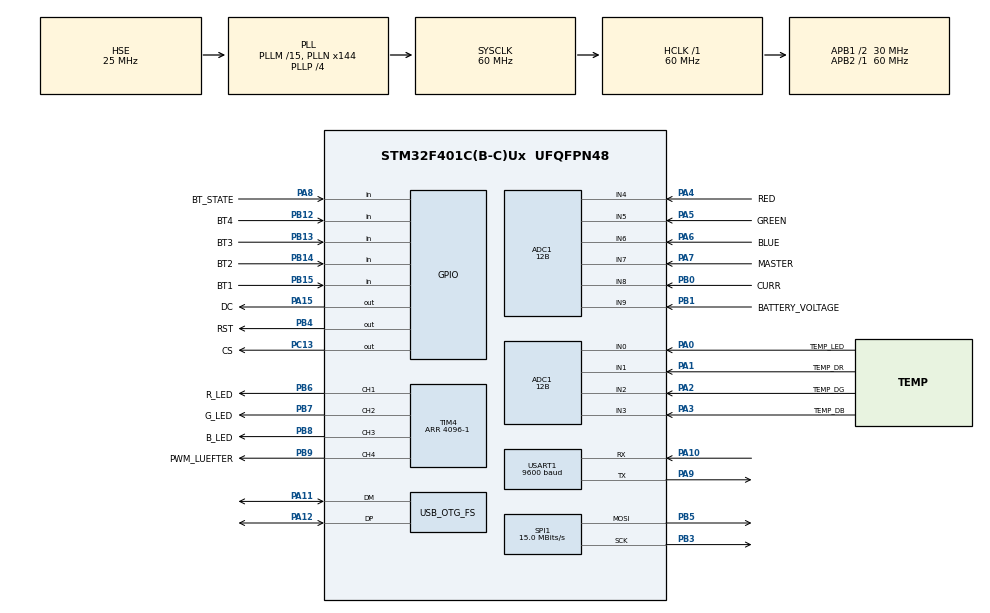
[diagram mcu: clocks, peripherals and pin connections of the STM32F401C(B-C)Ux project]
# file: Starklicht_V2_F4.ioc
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ADC1.Channel-0\#ChannelRegularConversion=ADC_CHANNEL_0
ADC1.Channel-1\#ChannelRegularConversion=ADC_CHANNEL_1
ADC1.Channel-2\#ChannelRegularConversion=ADC_CHANNEL_2
ADC1.Channel-3\#ChannelRegularConversion=ADC_CHANNEL_3
ADC1.Channel-4\#ChannelRegularConversion=ADC_CHANNEL_4
ADC1.Channel-5\#ChannelRegularConversion=ADC_CHANNEL_5
ADC1.Channel-6\#ChannelRegularConversion=ADC_CHANNEL_6
ADC1.Channel-7\#ChannelRegularConversion=ADC_CHANNEL_7
ADC1.Channel-8\#ChannelRegularConversion=ADC_CHANNEL_8
ADC1.Channel-9\#ChannelRegularConversion=ADC_CHANNEL_9
ADC1.ClockPrescaler=ADC_CLOCK_SYNC_PCLK_DIV8
ADC1.ContinuousConvMode=ENABLE
ADC1.DMAContinuousRequests=ENABLE
ADC1.EOCSelection=ADC_EOC_SINGLE_CONV
ADC1.ExternalTrigConv=ADC_SOFTWARE_START
ADC1.InjNumberOfConversion=0
ADC1.NbrOfConversion=10
ADC1.NbrOfConversionFlag=1
ADC1.Rank-0\#ChannelRegularConversion=1
ADC1.Rank-1\#ChannelRegularConversion=2
ADC1.Rank-2\#ChannelRegularConversion=3
ADC1.Rank-3\#ChannelRegularConversion=4
ADC1.Rank-4\#ChannelRegularConversion=5
ADC1.Rank-5\#ChannelRegularConversion=6
ADC1.Rank-6\#ChannelRegularConversion=7
ADC1.Rank-7\#ChannelRegularConversion=8
ADC1.Rank-8\#ChannelRegularConversion=9
ADC1.Rank-9\#ChannelRegularConversion=10
ADC1.Resolution=ADC_RESOLUTION_12B
ADC1.SamplingTime-0\#ChannelRegularConversion=ADC_SAMPLETIME_28CYCLES
ADC1.SamplingTime-1\#ChannelRegularConversion=ADC_SAMPLETIME_28CYCLES
ADC1.SamplingTime-2\#ChannelRegularConversion=ADC_SAMPLETIME_28CYCLES
ADC1.SamplingTime-3\#ChannelRegularConversion=ADC_SAMPLETIME_28CYCLES
ADC1.SamplingTime-4\#ChannelRegularConversion=ADC_SAMPLETIME_28CYCLES
ADC1.SamplingTime-5\#ChannelRegularConversion=ADC_SAMPLETIME_28CYCLES
ADC1.SamplingTime-6\#ChannelRegularConversion=ADC_SAMPLETIME_28CYCLES
ADC1.SamplingTime-7\#ChannelRegularConversion=ADC_SAMPLETIME_28CYCLES
ADC1.SamplingTime-8\#ChannelRegularConversion=ADC_SAMPLETIME_28CYCLES
ADC1.SamplingTime-9\#ChannelRegularConversion=ADC_SAMPLETIME_28CYCLES
ADC1.master=1
Dma.ADC1.0.Direction=DMA_PERIPH_TO_MEMORY
Dma.ADC1.0.FIFOMode=DMA_FIFOMODE_DISABLE
Dma.ADC1.0.Instance=DMA2_Stream4
Dma.ADC1.0.MemDataAlignment=DMA_MDATAALIGN_HALFWORD
Dma.ADC1.0.MemInc=DMA_MINC_ENABLE
Dma.ADC1.0.Mode=DMA_CIRCULAR
Dma.ADC1.0.PeriphDataAlignment=DMA_PDATAALIGN_HALFWORD
Dma.ADC1.0.PeriphInc=DMA_PINC_DISABLE
Dma.ADC1.0.Priority=DMA_PRIORITY_LOW
Dma.Request0=ADC1
Mcu.Family=STM32F4
Mcu.Name=STM32F401C(B-C)Ux
Mcu.Package=UFQFPN48
NVIC.DMA2_Stream4_IRQn=true\:0\:0\:false\:false\:true\:false\:true\:true
NVIC.OTG_FS_IRQn=true\:0\:0\:false\:false\:true\:false\:true\:true
NVIC.PriorityGroup=NVIC_PRIORITYGROUP_4
NVIC.USART1_IRQn=true\:0\:0\:false\:false\:true\:true\:true\:true
PA0-WKUP.GPIO_Label=TEMP_LED
PA0-WKUP.Signal=SharedAnalog_PA0
PA1.GPIO_Label=TEMP_DR
PA1.Signal=SharedAnalog_PA1
PA10.Mode=Asynchronous
PA10.Signal=USART1_RX
PA11.Mode=Device_Only
PA11.Signal=USB_OTG_FS_DM
PA12.Mode=Device_Only
PA12.Signal=USB_OTG_FS_DP
PA13.Mode=Serial_Wire
PA13.Signal=SYS_JTMS-SWDIO
PA14.Mode=Serial_Wire
PA14.Signal=SYS_JTCK-SWCLK
PA15.GPIO_Label=DC
PA15.Signal=GPIO_Output
PA2.GPIO_Label=TEMP_DG
PA2.Signal=SharedAnalog_PA2
PA3.GPIO_Label=TEMP_DB
PA3.Signal=SharedAnalog_PA3
PA4.GPIO_Label=RED
PA4.Signal=SharedAnalog_PA4
PA5.GPIO_Label=GREEN
PA5.Signal=SharedAnalog_PA5
PA6.GPIO_Label=BLUE
PA6.Signal=SharedAnalog_PA6
PA7.GPIO_Label=MASTER
PA7.Signal=SharedAnalog_PA7
PA8.GPIO_Label=BT_STATE
PA8.Signal=GPIO_Input
PA9.Mode=Asynchronous
PA9.Signal=USART1_TX
PB0.GPIO_Label=CURR
PB0.Signal=SharedAnalog_PB0
PB1.GPIO_Label=BATTERY_VOLTAGE
PB1.Signal=SharedAnalog_PB1
PB12.GPIO_Label=BT4
PB12.Signal=GPIO_Input
PB13.GPIO_Label=BT3
PB13.Signal=GPIO_Input
PB14.GPIO_Label=BT2
PB14.Signal=GPIO_Input
PB15.GPIO_Label=BT1
PB15.Signal=GPIO_Input
PB3.Mode=TX_Only_Simplex_Unidirect_Master
PB3.Signal=SPI1_SCK
PB4.GPIO_Label=RST
PB4.Signal=GPIO_Output
PB5.Mode=TX_Only_Simplex_Unidirect_Master
PB5.Signal=SPI1_MOSI
PB6.GPIO_Label=R_LED
PB6.Signal=S_TIM4_CH1
PB7.GPIO_Label=G_LED
PB7.Signal=S_TIM4_CH2
PB8.GPIO_Label=B_LED
PB8.Signal=S_TIM4_CH3
PB9.GPIO_Label=PWM_LUEFTER
PB9.Signal=S_TIM4_CH4
PC13-ANTI_TAMP.GPIO_Label=CS
PC13-ANTI_TAMP.Signal=GPIO_Output
PH0\ -\ OSC_IN.Mode=HSE-External-Oscillator
PH0\ -\ OSC_IN.Signal=RCC_OSC_IN
PH1\ -\ OSC_OUT.Mode=HSE-External-Oscillator
PH1\ -\ OSC_OUT.Signal=RCC_OSC_OUT
ProjectManager.HeapSize=0x200
ProjectManager.StackSize=0x400
ProjectManager.TargetToolchain=STM32CubeIDE
RCC.48MHZClocksFreq_Value=48000000
RCC.AHBFreq_Value=60000000
RCC.APB1CLKDivider=RCC_HCLK_DIV2
RCC.APB1Freq_Value=30000000
RCC.APB1TimFreq_Value=60000000
RCC.APB2Freq_Value=60000000
RCC.APB2TimFreq_Value=60000000
RCC.CortexFreq_Value=60000000
RCC.HCLKFreq_Value=60000000
RCC.HSE_VALUE=25000000
RCC.HSI_VALUE=16000000
RCC.LSE_VALUE=32768
RCC.PLLM=15
RCC.PLLN=144
RCC.PLLP=RCC_PLLP_DIV4
RCC.PLLQ=5
RCC.PLLSourceVirtual=RCC_PLLSOURCE_HSE
RCC.SYSCLKFreq_VALUE=60000000
RCC.SYSCLKSource=RCC_SYSCLKSOURCE_PLLCLK
RCC.VCOOutputFreq_Value=240000000
SH.S_TIM4_CH1.0=TIM4_CH1,PWM Generation1 CH1
SH.S_TIM4_CH2.0=TIM4_CH2,PWM Generation2 CH2
SH.S_TIM4_CH3.0=TIM4_CH3,PWM Generation3 CH3
SH.S_TIM4_CH4.0=TIM4_CH4,PWM Generation4 CH4
SH.SharedAnalog_PA0.0=GPIO_Analog
SH.SharedAnalog_PA0.1=ADC1_IN0,IN0
SH.SharedAnalog_PA1.0=GPIO_Analog
SH.SharedAnalog_PA1.1=ADC1_IN1,IN1
SH.SharedAnalog_PA2.0=GPIO_Analog
SH.SharedAnalog_PA2.1=ADC1_IN2,IN2
SH.SharedAnalog_PA3.0=GPIO_Analog
SH.SharedAnalog_PA3.1=ADC1_IN3,IN3
SH.SharedAnalog_PA4.0=GPIO_Analog
SH.SharedAnalog_PA4.1=ADC1_IN4,IN4
SH.SharedAnalog_PA5.0=GPIO_Analog
SH.SharedAnalog_PA5.1=ADC1_IN5,IN5
SH.SharedAnalog_PA6.0=GPIO_Analog
SH.SharedAnalog_PA6.1=ADC1_IN6,IN6
SH.SharedAnalog_PA7.0=GPIO_Analog
SH.SharedAnalog_PA7.1=ADC1_IN7,IN7
SH.SharedAnalog_PB0.0=GPIO_Analog
SH.SharedAnalog_PB0.1=ADC1_IN8,IN8
SH.SharedAnalog_PB1.0=GPIO_Analog
SH.SharedAnalog_PB1.1=ADC1_IN9,IN9
SPI1.BaudRatePrescaler=SPI_BAUDRATEPRESCALER_4
SPI1.CalculateBaudRate=15.0 MBits/s
SPI1.Direction=SPI_DIRECTION_2LINES
SPI1.Mode=SPI_MODE_MASTER
SPI1.VirtualType=VM_MASTER
TIM4.Channel-PWM\ Generation1\ CH1=TIM_CHANNEL_1
TIM4.Channel-PWM\ Generation2\ CH2=TIM_CHANNEL_2
TIM4.Channel-PWM\ Generation3\ CH3=TIM_CHANNEL_3
TIM4.Channel-PWM\ Generation4\ CH4=TIM_CHANNEL_4
TIM4.Period=4096-1
USART1.BaudRate=9600
USART1.VirtualMode=VM_ASYNC
USB_DEVICE.CLASS_NAME_FS=CDC
USB_DEVICE.VirtualMode=Cdc
USB_DEVICE.VirtualModeFS=Cdc_FS
USB_OTG_FS.VirtualMode=Device_Only
VP_USB_DEVICE_VS_USB_DEVICE_CDC_FS.Mode=CDC_FS
board=custom

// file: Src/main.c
/* USER CODE BEGIN Header */
/**
 ******************************************************************************
 * @file           : main.c
 * @brief          : Main program body
 ******************************************************************************
 * @attention
 *
 * <h2><center>&copy; Copyright (c) 2021 STMicroelectronics.
 * All rights reserved.</center></h2>
 *
 * This software component is licensed by ST under Ultimate Liberty license
 * SLA0044, the "License"; You may not use this file except in compliance with
 * the License. You may obtain a copy of the License at:
 *                             www.st.com/SLA0044
 *
 ******************************************************************************
 */
/* USER CODE END Header */
#include "main.h"
/* USER CODE BEGIN Includes */
#include "starklicht.h"
/* USER CODE END Includes */

/* USER CODE BEGIN PD */
#define USE_BUTTONS 1
/* USER CODE END PD */

ADC_HandleTypeDef hadc1;
DMA_HandleTypeDef hdma_adc1;

SPI_HandleTypeDef hspi1;

TIM_HandleTypeDef htim4;

UART_HandleTypeDef huart1;

void SystemClock_Config(void);
static void MX_GPIO_Init(void);
static void MX_DMA_Init(void);
static void MX_TIM4_Init(void);
static void MX_SPI1_Init(void);
static void MX_ADC1_Init(void);
static void MX_USART1_UART_Init(void);

/* USER CODE BEGIN 0 */
static u8g2_t u8g2;

uint8_t buffer[512];
int numChars = 128;
uint8_t current_char;
int num_messages = 0;
uint8_t escapeSign = 0;
int num_chars;
uint16_t ndx = 0;
uint8_t payload = 0;
uint8_t endMarker = '\n';
uint16_t analogInputs[10];

uint8_t u8x8_stm32_gpio_and_delay(U8X8_UNUSED u8x8_t *u8x8,
                                  U8X8_UNUSED uint8_t msg, U8X8_UNUSED uint8_t arg_int,
                                  U8X8_UNUSED void *arg_ptr)
{
  switch (msg)
  {
  case U8X8_MSG_GPIO_AND_DELAY_INIT:
    HAL_Delay(1);
    break;
  case U8X8_MSG_DELAY_MILLI:
    HAL_Delay(arg_int);
    break;
  case U8X8_MSG_GPIO_DC:
    HAL_GPIO_WritePin(DC_GPIO_Port, DC_Pin, arg_int);
    break;
  case U8X8_MSG_GPIO_RESET:
    HAL_GPIO_WritePin(RST_GPIO_Port, RST_Pin, arg_int);
    break;
  case U8X8_MSG_GPIO_CS:
    HAL_GPIO_WritePin(CS_GPIO_Port, CS_Pin, arg_int);

    break;
  }
  return 1;
}

uint8_t u8x8_byte_4wire_hw_spi(u8x8_t *u8x8, uint8_t msg, uint8_t arg_int,
                               void *arg_ptr)
{
  switch (msg)
  {
  case U8X8_MSG_BYTE_SEND:
    HAL_SPI_Transmit(&hspi1, (uint8_t *)arg_ptr, arg_int, 10000);
    break;
  case U8X8_MSG_BYTE_INIT:
    break;
  case U8X8_MSG_BYTE_SET_DC:
    HAL_GPIO_WritePin(DC_GPIO_Port, DC_Pin, arg_int);
    break;
  case U8X8_MSG_BYTE_START_TRANSFER:
    break;
  case U8X8_MSG_BYTE_END_TRANSFER:
    break;
  default:
    return 0;
  }
  return 1;
}
/* USER CODE END 0 */

int main(void)
{

  /* MCU Configuration--------------------------------------------------------*/

  /* Reset of all peripherals, Initializes the Flash interface and the Systick. */
  HAL_Init();

  /* Configure the system clock */
  SystemClock_Config();

  /* Initialize all configured peripherals */
  MX_GPIO_Init();
  MX_DMA_Init();
  MX_TIM4_Init();
  MX_SPI1_Init();
  MX_ADC1_Init();
  MX_USART1_UART_Init();
  /* USER CODE BEGIN 2 */
  HAL_UART_Receive_IT(&huart1, &current_char, 1);

  HAL_TIM_PWM_Start(&htim4, TIM_CHANNEL_1);
  HAL_TIM_PWM_Start(&htim4, TIM_CHANNEL_2);
  HAL_TIM_PWM_Start(&htim4, TIM_CHANNEL_3);
  HAL_TIM_PWM_Start(&htim4, TIM_CHANNEL_4);

  TIM2->CCR1 = 0;
  if (HAL_ADC_Start_DMA(&hadc1, (uint32_t *)analogInputs, 10) != HAL_OK)
  {
    /* Start Conversation Error */
    Error_Handler();
  }

  for (int i = 0; i < 3; i++)
  {
    HAL_GPIO_TogglePin(LED1_GPIO_Port, LED1_Pin);
    HAL_Delay(10);
  }

  u8g2_Setup_sh1106_128x64_noname_f(&u8g2, U8G2_R0, u8x8_byte_4wire_hw_spi, u8x8_stm32_gpio_and_delay);
  u8g2_InitDisplay(&u8g2);
  u8g2_SetFlipMode(&u8g2, 0);
  u8g2_SetPowerSave(&u8g2, 0);
  setup(&analogInputs, &u8g2, USE_BUTTONS);
  int batteryEnergy = getBatteryEnergy();
  char num[10];
  sprintf(num, "%dWh", batteryEnergy);

  for (uint8_t i = 78; i > 38; i--)
  {
    u8g2_FirstPage(&u8g2);
    u8g2_SetFont(&u8g2, u8g2_font_luBS12_te);
    u8g2_DrawStr(&u8g2, 8, i, "STARKLICHT");
    u8g2_SetFont(&u8g2, u8g2_font_helvR08_te);
    u8g2_DrawStr(&u8g2, 48, 8, num);
    u8g2_NextPage(&u8g2);
    HAL_Delay(2);
  }
  HAL_Delay(500);

  /* USER CODE END 2 */

  /* Infinite loop */
  /* USER CODE BEGIN WHILE */

  while (1)
  {
    u8g2_FirstPage(&u8g2);
    do
    {
      loop(HAL_GetTick());
    } while (u8g2_NextPage(&u8g2));
    /* USER CODE END WHILE */

  }
}

void SystemClock_Config(void)
{
  RCC_OscInitTypeDef RCC_OscInitStruct = {0};
  RCC_ClkInitTypeDef RCC_ClkInitStruct = {0};

  /** Configure the main internal regulator output voltage
   */
  __HAL_RCC_PWR_CLK_ENABLE();
  __HAL_PWR_VOLTAGESCALING_CONFIG(PWR_REGULATOR_VOLTAGE_SCALE2);
  /** Initializes the RCC Oscillators according to the specified parameters
   * in the RCC_OscInitTypeDef structure.
   */
  RCC_OscInitStruct.OscillatorType = RCC_OSCILLATORTYPE_HSE;
  RCC_OscInitStruct.HSEState = RCC_HSE_ON;
  RCC_OscInitStruct.PLL.PLLState = RCC_PLL_ON;
  RCC_OscInitStruct.PLL.PLLSource = RCC_PLLSOURCE_HSE;
  RCC_OscInitStruct.PLL.PLLM = 15;
  RCC_OscInitStruct.PLL.PLLN = 144;
  RCC_OscInitStruct.PLL.PLLP = RCC_PLLP_DIV4;
  RCC_OscInitStruct.PLL.PLLQ = 5;
  if (HAL_RCC_OscConfig(&RCC_OscInitStruct) != HAL_OK)
  {
    Error_Handler();
  }
  /** Initializes the CPU, AHB and APB buses clocks
   */
  RCC_ClkInitStruct.ClockType = RCC_CLOCKTYPE_HCLK | RCC_CLOCKTYPE_SYSCLK | RCC_CLOCKTYPE_PCLK1 | RCC_CLOCKTYPE_PCLK2;
  RCC_ClkInitStruct.SYSCLKSource = RCC_SYSCLKSOURCE_PLLCLK;
  RCC_ClkInitStruct.AHBCLKDivider = RCC_SYSCLK_DIV1;
  RCC_ClkInitStruct.APB1CLKDivider = RCC_HCLK_DIV2;
  RCC_ClkInitStruct.APB2CLKDivider = RCC_HCLK_DIV1;

  if (HAL_RCC_ClockConfig(&RCC_ClkInitStruct, FLASH_LATENCY_1) != HAL_OK)
  {
    Error_Handler();
  }
}

static void MX_ADC1_Init(void)
{

  ADC_ChannelConfTypeDef sConfig = {0};

  /** Configure the global features of the ADC (Clock, Resolution, Data Alignment and number of conversion)
   */
  hadc1.Instance = ADC1;
  hadc1.Init.ClockPrescaler = ADC_CLOCK_SYNC_PCLK_DIV8;
  hadc1.Init.Resolution = ADC_RESOLUTION_12B;
  hadc1.Init.ScanConvMode = ENABLE;
  hadc1.Init.ContinuousConvMode = ENABLE;
  hadc1.Init.DiscontinuousConvMode = DISABLE;
  hadc1.Init.ExternalTrigConvEdge = ADC_EXTERNALTRIGCONVEDGE_NONE;
  hadc1.Init.ExternalTrigConv = ADC_SOFTWARE_START;
  hadc1.Init.DataAlign = ADC_DATAALIGN_RIGHT;
  hadc1.Init.NbrOfConversion = 10;
  hadc1.Init.DMAContinuousRequests = ENABLE;
  hadc1.Init.EOCSelection = ADC_EOC_SINGLE_CONV;
  if (HAL_ADC_Init(&hadc1) != HAL_OK)
  {
    Error_Handler();
  }
  /** Configure for the selected ADC regular channel its corresponding rank in the sequencer and its sample time.
   */
  sConfig.Channel = ADC_CHANNEL_0;
  sConfig.Rank = 1;
  sConfig.SamplingTime = ADC_SAMPLETIME_28CYCLES;
  if (HAL_ADC_ConfigChannel(&hadc1, &sConfig) != HAL_OK)
  {
    Error_Handler();
  }
  /** Configure for the selected ADC regular channel its corresponding rank in the sequencer and its sample time.
   */
  sConfig.Channel = ADC_CHANNEL_1;
  sConfig.Rank = 2;
  if (HAL_ADC_ConfigChannel(&hadc1, &sConfig) != HAL_OK)
  {
    Error_Handler();
  }
  /** Configure for the selected ADC regular channel its corresponding rank in the sequencer and its sample time.
   */
  sConfig.Channel = ADC_CHANNEL_2;
  sConfig.Rank = 3;
  if (HAL_ADC_ConfigChannel(&hadc1, &sConfig) != HAL_OK)
  {
    Error_Handler();
  }
  /** Configure for the selected ADC regular channel its corresponding rank in the sequencer and its sample time.
   */
  sConfig.Channel = ADC_CHANNEL_3;
  sConfig.Rank = 4;
  if (HAL_ADC_ConfigChannel(&hadc1, &sConfig) != HAL_OK)
  {
    Error_Handler();
  }
  /** Configure for the selected ADC regular channel its corresponding rank in the sequencer and its sample time.
   */
  sConfig.Channel = ADC_CHANNEL_4;
  sConfig.Rank = 5;
  if (HAL_ADC_ConfigChannel(&hadc1, &sConfig) != HAL_OK)
  {
    Error_Handler();
  }
  /** Configure for the selected ADC regular channel its corresponding rank in the sequencer and its sample time.
   */
  sConfig.Channel = ADC_CHANNEL_5;
  sConfig.Rank = 6;
  if (HAL_ADC_ConfigChannel(&hadc1, &sConfig) != HAL_OK)
  {
    Error_Handler();
  }
  /** Configure for the selected ADC regular channel its corresponding rank in the sequencer and its sample time.
   */
  sConfig.Channel = ADC_CHANNEL_6;
  sConfig.Rank = 7;
  if (HAL_ADC_ConfigChannel(&hadc1, &sConfig) != HAL_OK)
  {
    Error_Handler();
  }
  /** Configure for the selected ADC regular channel its corresponding rank in the sequencer and its sample time.
   */
  sConfig.Channel = ADC_CHANNEL_7;
  sConfig.Rank = 8;
  if (HAL_ADC_ConfigChannel(&hadc1, &sConfig) != HAL_OK)
  {
    Error_Handler();
  }
  /** Configure for the selected ADC regular channel its corresponding rank in the sequencer and its sample time.
   */
  sConfig.Channel = ADC_CHANNEL_8;
  sConfig.Rank = 9;
  if (HAL_ADC_ConfigChannel(&hadc1, &sConfig) != HAL_OK)
  {
    Error_Handler();
  }
  /** Configure for the selected ADC regular channel its corresponding rank in the sequencer and its sample time.
   */
  sConfig.Channel = ADC_CHANNEL_9;
  sConfig.Rank = 10;
  if (HAL_ADC_ConfigChannel(&hadc1, &sConfig) != HAL_OK)
  {
    Error_Handler();
  }
}

static void MX_SPI1_Init(void)
{

  /* SPI1 parameter configuration*/
  hspi1.Instance = SPI1;
  hspi1.Init.Mode = SPI_MODE_MASTER;
  hspi1.Init.Direction = SPI_DIRECTION_2LINES;
  hspi1.Init.DataSize = SPI_DATASIZE_8BIT;
  hspi1.Init.CLKPolarity = SPI_POLARITY_LOW;
  hspi1.Init.CLKPhase = SPI_PHASE_1EDGE;
  hspi1.Init.NSS = SPI_NSS_SOFT;
  hspi1.Init.BaudRatePrescaler = SPI_BAUDRATEPRESCALER_4;
  hspi1.Init.FirstBit = SPI_FIRSTBIT_MSB;
  hspi1.Init.TIMode = SPI_TIMODE_DISABLE;
  hspi1.Init.CRCCalculation = SPI_CRCCALCULATION_DISABLE;
  hspi1.Init.CRCPolynomial = 10;
  if (HAL_SPI_Init(&hspi1) != HAL_OK)
  {
    Error_Handler();
  }
}

static void MX_TIM4_Init(void)
{

  TIM_MasterConfigTypeDef sMasterConfig = {0};
  TIM_OC_InitTypeDef sConfigOC = {0};

  htim4.Instance = TIM4;
  htim4.Init.Prescaler = 0;
  htim4.Init.CounterMode = TIM_COUNTERMODE_UP;
  htim4.Init.Period = 4096 - 1;
  htim4.Init.ClockDivision = TIM_CLOCKDIVISION_DIV1;
  htim4.Init.AutoReloadPreload = TIM_AUTORELOAD_PRELOAD_DISABLE;
  if (HAL_TIM_PWM_Init(&htim4) != HAL_OK)
  {
    Error_Handler();
  }
  sMasterConfig.MasterOutputTrigger = TIM_TRGO_RESET;
  sMasterConfig.MasterSlaveMode = TIM_MASTERSLAVEMODE_DISABLE;
  if (HAL_TIMEx_MasterConfigSynchronization(&htim4, &sMasterConfig) != HAL_OK)
  {
    Error_Handler();
  }
  sConfigOC.OCMode = TIM_OCMODE_PWM1;
  sConfigOC.Pulse = 0;
  sConfigOC.OCPolarity = TIM_OCPOLARITY_HIGH;
  sConfigOC.OCFastMode = TIM_OCFAST_DISABLE;
  if (HAL_TIM_PWM_ConfigChannel(&htim4, &sConfigOC, TIM_CHANNEL_1) != HAL_OK)
  {
    Error_Handler();
  }
  if (HAL_TIM_PWM_ConfigChannel(&htim4, &sConfigOC, TIM_CHANNEL_2) != HAL_OK)
  {
    Error_Handler();
  }
  if (HAL_TIM_PWM_ConfigChannel(&htim4, &sConfigOC, TIM_CHANNEL_3) != HAL_OK)
  {
    Error_Handler();
  }
  if (HAL_TIM_PWM_ConfigChannel(&htim4, &sConfigOC, TIM_CHANNEL_4) != HAL_OK)
  {
    Error_Handler();
  }
  HAL_TIM_MspPostInit(&htim4);
}

static void MX_USART1_UART_Init(void)
{

  huart1.Instance = USART1;
  huart1.Init.BaudRate = 9600;
  huart1.Init.WordLength = UART_WORDLENGTH_8B;
  huart1.Init.StopBits = UART_STOPBITS_1;
  huart1.Init.Parity = UART_PARITY_NONE;
  huart1.Init.Mode = UART_MODE_TX_RX;
  huart1.Init.HwFlowCtl = UART_HWCONTROL_NONE;
  huart1.Init.OverSampling = UART_OVERSAMPLING_16;
  if (HAL_UART_Init(&huart1) != HAL_OK)
  {
    Error_Handler();
  }
}

static void MX_DMA_Init(void)
{

  /* DMA controller clock enable */
  __HAL_RCC_DMA2_CLK_ENABLE();

  /* DMA interrupt init */
  /* DMA2_Stream4_IRQn interrupt configuration */
  HAL_NVIC_SetPriority(DMA2_Stream4_IRQn, 0, 0);
  HAL_NVIC_EnableIRQ(DMA2_Stream4_IRQn);
}

static void MX_GPIO_Init(void)
{
  GPIO_InitTypeDef GPIO_InitStruct = {0};

  /* GPIO Ports Clock Enable */
  __HAL_RCC_GPIOC_CLK_ENABLE();
  __HAL_RCC_GPIOH_CLK_ENABLE();
  __HAL_RCC_GPIOA_CLK_ENABLE();
  __HAL_RCC_GPIOB_CLK_ENABLE();

  /*Configure GPIO pin Output Level */
  HAL_GPIO_WritePin(LED1_GPIO_Port, LED1_Pin, GPIO_PIN_RESET);

  /*Configure GPIO pin Output Level */
  HAL_GPIO_WritePin(GPIOA, CS_Pin | DC_Pin, GPIO_PIN_RESET);

  /*Configure GPIO pin Output Level */
  HAL_GPIO_WritePin(RST_GPIO_Port, RST_Pin, GPIO_PIN_RESET);

  /*Configure GPIO pin : LED1_Pin */
  GPIO_InitStruct.Pin = LED1_Pin;
  GPIO_InitStruct.Mode = GPIO_MODE_OUTPUT_PP;
  GPIO_InitStruct.Pull = GPIO_NOPULL;
  GPIO_InitStruct.Speed = GPIO_SPEED_FREQ_LOW;
  HAL_GPIO_Init(LED1_GPIO_Port, &GPIO_InitStruct);

  /*Configure GPIO pins : BT4_Pin BT3_Pin BT2_Pin BT1_Pin */
  GPIO_InitStruct.Pin = BT4_Pin | BT3_Pin | BT2_Pin | BT1_Pin;
  GPIO_InitStruct.Mode = GPIO_MODE_INPUT;
  GPIO_InitStruct.Pull = GPIO_NOPULL;
  HAL_GPIO_Init(GPIOB, &GPIO_InitStruct);

  /*Configure GPIO pin : BT_STATE_Pin */
  GPIO_InitStruct.Pin = BT_STATE_Pin;
  GPIO_InitStruct.Mode = GPIO_MODE_INPUT;
  GPIO_InitStruct.Pull = GPIO_NOPULL;
  HAL_GPIO_Init(BT_STATE_GPIO_Port, &GPIO_InitStruct);

  /*Configure GPIO pins : CS_Pin DC_Pin */
  GPIO_InitStruct.Pin = CS_Pin | DC_Pin;
  GPIO_InitStruct.Mode = GPIO_MODE_OUTPUT_PP;
  GPIO_InitStruct.Pull = GPIO_NOPULL;
  GPIO_InitStruct.Speed = GPIO_SPEED_FREQ_LOW;
  HAL_GPIO_Init(GPIOA, &GPIO_InitStruct);

  /*Configure GPIO pin : RST_Pin */
  GPIO_InitStruct.Pin = RST_Pin;
  GPIO_InitStruct.Mode = GPIO_MODE_OUTPUT_PP;
  GPIO_InitStruct.Pull = GPIO_NOPULL;
  GPIO_InitStruct.Speed = GPIO_SPEED_FREQ_LOW;
  HAL_GPIO_Init(RST_GPIO_Port, &GPIO_InitStruct);
}

/* USER CODE BEGIN 4 */
void HAL_UART_RxCpltCallback(UART_HandleTypeDef *huart)
{
  if (huart->Instance == USART1)
  {
    if (payload == 1 && current_char == endMarker)
    {
      buffer[ndx] = '\0';
      ndx = 0;
      payload = 0;
      // TODO: Controller updaten
      num_messages++;
      HAL_UART_Receive_IT(&huart1, &current_char, 1);
      parseMessage(&buffer);
      // build message
      return;
    }
    if ((current_char != escapeSign) | (payload == 1))
    {
      buffer[ndx] = current_char;
      ndx++;
      if (ndx >= numChars)
      {
        ndx = numChars - 1;
      }
      payload = 0;
    }
    else
    {
      payload = 1;
    }
    HAL_UART_Receive_IT(&huart1, &current_char, 1);
  }
}
/* USER CODE END 4 */

void Error_Handler(void)
{
  /* USER CODE BEGIN Error_Handler_Debug */
  /* User can add his own implementation to report the HAL error return state */
  __disable_irq();
  while (1)
  {
    HAL_GPIO_TogglePin(LED1_GPIO_Port, LED1_Pin);
    HAL_Delay(100);
  }
  /* USER CODE END Error_Handler_Debug */
}

/************************ (C) COPYRIGHT STMicroelectronics *****END OF FILE****/
